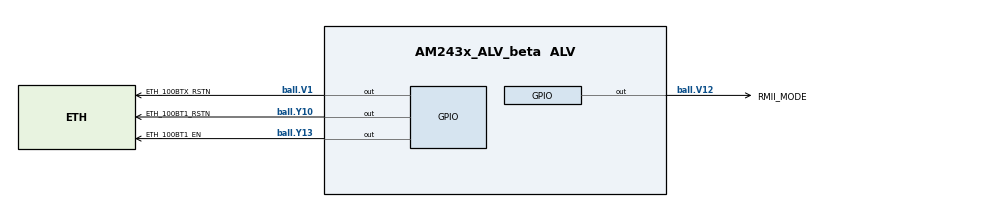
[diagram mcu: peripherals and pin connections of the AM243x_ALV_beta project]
/**
 * @cliArgs --device "AM243x_ALV_beta" --package "ALV" --part "ALV" --context "r5fss0-0" --product "MCU_PLUS_SDK_AM243x@08.05.00"
 * @versions {"tool":"1.14.0+2667"}
 */

/**
 * Import the modules used in this configuration.
 */
const gpio       = scripting.addModule("/drivers/gpio/gpio", {}, false);
const gpio1      = gpio.addInstance();
const gpio2      = gpio.addInstance();
const gpio3      = gpio.addInstance();
const gpio4      = gpio.addInstance();
const pruicss    = scripting.addModule("/drivers/pruicss/pruicss", {}, false);
const pruicss1   = pruicss.addInstance();
const debug_log  = scripting.addModule("/kernel/dpl/debug_log");
const mpu_armv7  = scripting.addModule("/kernel/dpl/mpu_armv7", {}, false);
const mpu_armv71 = mpu_armv7.addInstance();
const mpu_armv72 = mpu_armv7.addInstance();
const mpu_armv73 = mpu_armv7.addInstance();
const mpu_armv74 = mpu_armv7.addInstance();
const mpu_armv75 = mpu_armv7.addInstance();
const mpu_armv76 = mpu_armv7.addInstance();
const mpu_armv77 = mpu_armv7.addInstance();
const enet_cpsw  = scripting.addModule("/networking/enet_cpsw/enet_cpsw", {}, false);
const enet_cpsw1 = enet_cpsw.addInstance();

/**
 * Write custom configuration values to the imported modules.
 */
gpio1.$name                = "ETH_100BT1_EN";
gpio1.pinDir               = "OUTPUT";
gpio1.GPIO.gpioPin.rx      = false;
gpio1.GPIO.gpioPin.$assign = "ball.Y13";

gpio2.pinDir               = "OUTPUT";
gpio2.$name                = "ETH_100BT1_RSTN";
gpio2.GPIO.gpioPin.rx      = false;
gpio2.GPIO.gpioPin.$assign = "ball.Y10";

gpio3.pinDir               = "OUTPUT";
gpio3.$name                = "ETH_100BTX_RSTN";
gpio3.GPIO.gpioPin.rx      = false;
gpio3.GPIO.gpioPin.$assign = "ball.V1";

gpio4.pinDir               = "OUTPUT";
gpio4.$name                = "RMII_MODE";
gpio4.GPIO.gpioPin.rx      = false;
gpio4.GPIO.gpioPin.$assign = "ball.V12";

pruicss1.$name                           = "CONFIG_PRU_ICSS1";
pruicss1.instance                        = "ICSSG1";
pruicss1.AdditionalICSSSettings[0].$name = "CONFIG_PRU_ICSS_IO0";

debug_log.enableUartLog = true;
debug_log.enableCssLog  = false;
debug_log.uartLog.$name = "CONFIG_UART0";

mpu_armv71.$name             = "CONFIG_MPU_REGION0";
mpu_armv71.size              = 31;
mpu_armv71.attributes        = "Device";
mpu_armv71.accessPermissions = "Supervisor RD+WR, User RD";
mpu_armv71.allowExecute      = false;

mpu_armv72.$name             = "CONFIG_MPU_REGION1";
mpu_armv72.size              = 15;
mpu_armv72.accessPermissions = "Supervisor RD+WR, User RD";

mpu_armv73.$name             = "CONFIG_MPU_REGION2";
mpu_armv73.baseAddr          = 0x41010000;
mpu_armv73.size              = 15;
mpu_armv73.accessPermissions = "Supervisor RD+WR, User RD";

mpu_armv74.$name             = "CONFIG_MPU_REGION3";
mpu_armv74.accessPermissions = "Supervisor RD+WR, User RD";
mpu_armv74.baseAddr          = 0x70000000;
mpu_armv74.size              = 23;

mpu_armv75.$name             = "CONFIG_MPU_REGION4";
mpu_armv75.accessPermissions = "Supervisor RD+WR, User RD";
mpu_armv75.baseAddr          = 0x80000000;
mpu_armv75.size              = 31;

mpu_armv76.$name             = "CONFIG_MPU_REGION5";
mpu_armv76.accessPermissions = "Supervisor RD+WR, User RD";
mpu_armv76.baseAddr          = 0xA5000000;
mpu_armv76.size              = 23;
mpu_armv76.attributes        = "NonCached";

mpu_armv77.$name    = "CONFIG_MPU_REGION6";
mpu_armv77.size     = 27;
mpu_armv77.baseAddr = 0x60000000;

enet_cpsw1.$name                           = "CONFIG_ENET_CPSW0";
enet_cpsw1.PktInfoOnlyEnable               = true;
enet_cpsw1.LargePoolPktCount               = 32;
enet_cpsw1.mdioMode                        = "MDIO_MODE_MANUAL";
enet_cpsw1.macOnlyEn_hostPort              = true;
enet_cpsw1.macOnlyEn_macPort1              = true;
enet_cpsw1.macOnlyEn_macPort2              = true;
enet_cpsw1.ExternalPhyMgmtEnable           = true;
enet_cpsw1.txDmaChannel[0].$name           = "ENET_DMA_TX_CH0";
enet_cpsw1.rxDmaChannel[0].$name           = "ENET_DMA_RX_CH0";
enet_cpsw1.pinmux[0].$name                 = "ENET_CPSW_PINMUX0";
enet_cpsw1.pinmux[0].phyToMacInterfaceMode = "RMII";
enet_cpsw1.pinmux[0].MDIO.$assign          = "MDIO0";
enet_cpsw1.pinmux[0].MDIO.MDC.$assign      = "ball.Y6";
enet_cpsw1.pinmux[0].MDIO.MDIO.$assign     = "ball.AA6";
enet_cpsw1.netifInstance.create(1);
enet_cpsw1.netifInstance[0].$name          = "NETIF_INST_ID0";

const udma         = scripting.addModule("/drivers/udma/udma", {}, false);
const udma1        = udma.addInstance({}, false);
enet_cpsw1.udmaDrv = udma1;

/**
 * Pinmux solution for unlocked pins/peripherals. This ensures that minor changes to the automatic solver in a future
 * version of the tool will not impact the pinmux you originally saw.  These lines can be completely deleted in order to
 * re-solve from scratch.
 */
gpio1.GPIO.$suggestSolution                             = "GPIO0";
gpio2.GPIO.$suggestSolution                             = "GPIO0";
gpio3.GPIO.$suggestSolution                             = "GPIO1";
gpio4.GPIO.$suggestSolution                             = "GPIO0";
debug_log.uartLog.UART.$suggestSolution                 = "USART0";
debug_log.uartLog.UART.RXD.$suggestSolution             = "ball.D15";
debug_log.uartLog.UART.TXD.$suggestSolution             = "ball.C16";
enet_cpsw1.pinmux[0].RMII.$suggestSolution              = "RMII";
enet_cpsw1.pinmux[0].RMII.RMII_REF_CLK.$suggestSolution = "ball.AA5";
enet_cpsw1.pinmux[0].RMII.RMII1_CRS_DV.$suggestSolution = "ball.R2";
enet_cpsw1.pinmux[0].RMII.RMII1_RXD0.$suggestSolution   = "ball.W5";
enet_cpsw1.pinmux[0].RMII.RMII1_RXD1.$suggestSolution   = "ball.Y5";
enet_cpsw1.pinmux[0].RMII.RMII1_RX_ER.$suggestSolution  = "ball.W6";
enet_cpsw1.pinmux[0].RMII.RMII1_TXD0.$suggestSolution   = "ball.V6";
enet_cpsw1.pinmux[0].RMII.RMII1_TXD1.$suggestSolution   = "ball.V5";
enet_cpsw1.pinmux[0].RMII.RMII1_TX_EN.$suggestSolution  = "ball.P5";
enet_cpsw1.pinmux[0].RMII.RMII2_CRS_DV.$suggestSolution = "ball.U10";
enet_cpsw1.pinmux[0].RMII.RMII2_RXD0.$suggestSolution   = "ball.W11";
enet_cpsw1.pinmux[0].RMII.RMII2_RXD1.$suggestSolution   = "ball.V11";
enet_cpsw1.pinmux[0].RMII.RMII2_RX_ER.$suggestSolution  = "ball.W12";
enet_cpsw1.pinmux[0].RMII.RMII2_TXD0.$suggestSolution   = "ball.AA10";
enet_cpsw1.pinmux[0].RMII.RMII2_TXD1.$suggestSolution   = "ball.V10";
enet_cpsw1.pinmux[0].RMII.RMII2_TX_EN.$suggestSolution  = "ball.Y11";
